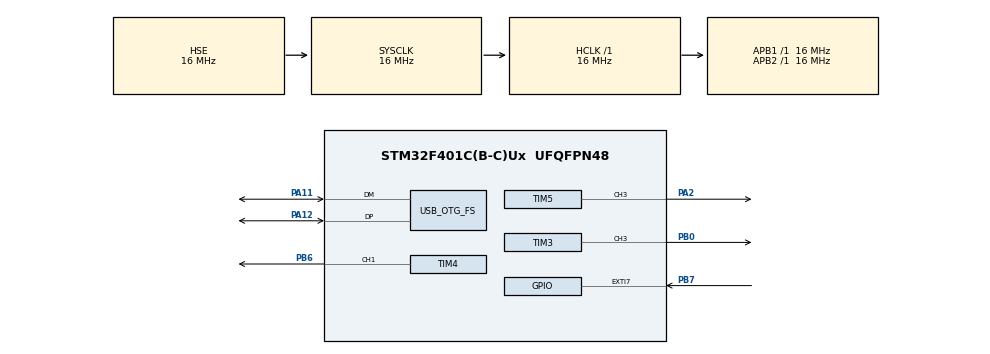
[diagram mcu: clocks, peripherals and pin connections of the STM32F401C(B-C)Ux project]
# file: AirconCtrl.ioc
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IWDG.Reload=4095
Mcu.Family=STM32F4
Mcu.Name=STM32F401C(B-C)Ux
Mcu.Package=UFQFPN48
NVIC.EXTI9_5_IRQn=true\:0\:0\:false\:false\:true\:true\:true\:true
NVIC.OTG_FS_IRQn=true\:0\:0\:false\:false\:true\:false\:true\:true
NVIC.PriorityGroup=NVIC_PRIORITYGROUP_4
NVIC.TIM2_IRQn=true\:0\:0\:false\:false\:true\:true\:true\:true
NVIC.TIM5_IRQn=true\:0\:0\:false\:false\:true\:true\:true\:true
PA11.Mode=Device_Only
PA11.Signal=USB_OTG_FS_DM
PA12.Mode=Device_Only
PA12.Signal=USB_OTG_FS_DP
PA13.Mode=Serial_Wire
PA13.Signal=SYS_JTMS-SWDIO
PA14.Mode=Serial_Wire
PA14.Signal=SYS_JTCK-SWCLK
PA2.Signal=S_TIM5_CH3
PB0.Signal=S_TIM3_CH3
PB6.Signal=S_TIM4_CH1
PB7.GPIO_ModeDefaultEXTI=GPIO_MODE_IT_FALLING
PB7.Signal=GPXTI7
PH0\ -\ OSC_IN.Mode=HSE-External-Oscillator
PH0\ -\ OSC_IN.Signal=RCC_OSC_IN
PH1\ -\ OSC_OUT.Mode=HSE-External-Oscillator
PH1\ -\ OSC_OUT.Signal=RCC_OSC_OUT
ProjectManager.HeapSize=0x200
ProjectManager.StackSize=0x400
ProjectManager.TargetToolchain=Makefile
RCC.48MHZClocksFreq_Value=48000000
RCC.AHBFreq_Value=16000000
RCC.APB1Freq_Value=16000000
RCC.APB2Freq_Value=16000000
RCC.CortexFreq_Value=16000000
RCC.HSE_VALUE=16000000
RCC.HSI_VALUE=16000000
RCC.LSE_VALUE=32768
RCC.PLLM=8
RCC.PLLN=72
RCC.PLLQ=3
RCC.SYSCLKFreq_VALUE=16000000
RCC.SYSCLKSource=RCC_SYSCLKSOURCE_HSE
RCC.VCOOutputFreq_Value=144000000
SH.S_TIM3_CH3.0=TIM3_CH3,PWM Generation3 CH3
SH.S_TIM4_CH1.0=TIM4_CH1,PWM Generation1 CH1
SH.S_TIM5_CH3.0=TIM5_CH3,PWM Generation3 CH3
TIM1.Prescaler=159
TIM2.AutoReloadPreload=TIM_AUTORELOAD_PRELOAD_ENABLE
TIM2.Period=99
TIM2.Prescaler=15999
TIM2.TIM_MasterOutputTrigger=TIM_TRGO_UPDATE
TIM2.TIM_MasterSlaveMode=TIM_MASTERSLAVEMODE_ENABLE
TIM3.AutoReloadPreload=TIM_AUTORELOAD_PRELOAD_ENABLE
TIM3.Channel-PWM\ Generation3\ CH3=TIM_CHANNEL_3
TIM3.OCMode_PWM-PWM\ Generation3\ CH3=TIM_OCMODE_PWM1
TIM3.OCPolarity_3=TIM_OCPOLARITY_LOW
TIM3.Period=420
TIM3.Pulse-PWM\ Generation3\ CH3=150
TIM3.TIM_MasterOutputTrigger=TIM_TRGO_UPDATE
TIM3.TIM_MasterSlaveMode=TIM_MASTERSLAVEMODE_ENABLE
TIM4.AutoReloadPreload=TIM_AUTORELOAD_PRELOAD_ENABLE
TIM4.Channel-PWM\ Generation1\ CH1=TIM_CHANNEL_1
TIM4.OCFastMode_PWM-PWM\ Generation1\ CH1=TIM_OCFAST_DISABLE
TIM4.Period=420
TIM4.Pulse-PWM\ Generation1\ CH1=150
TIM4.TIM_MasterOutputTrigger=TIM_TRGO_UPDATE
TIM4.TIM_MasterSlaveMode=TIM_MASTERSLAVEMODE_ENABLE
TIM5.AutoReloadPreload=TIM_AUTORELOAD_PRELOAD_ENABLE
TIM5.Channel-PWM\ Generation3\ CH3=TIM_CHANNEL_3
TIM5.Period=27839
TIM5.Prescaler=1
TIM5.TIM_MasterOutputTrigger=TIM_TRGO_UPDATE
TIM5.TIM_MasterSlaveMode=TIM_MASTERSLAVEMODE_ENABLE
USB_DEVICE.CLASS_NAME_FS=CDC
USB_DEVICE.VirtualMode=Cdc
USB_DEVICE.VirtualModeFS=Cdc_FS
USB_OTG_FS.VirtualMode=Device_Only
VP_IWDG_VS_IWDG.Mode=IWDG_Activate
VP_TIM1_VS_ClockSourceINT.Mode=Internal
VP_TIM2_VS_ClockSourceINT.Mode=Internal
VP_TIM5_VS_ClockSourceINT.Mode=Internal
VP_USB_DEVICE_VS_USB_DEVICE_CDC_FS.Mode=CDC_FS
VP_WWDG_VS_WWDG.Mode=WWDG_Activate
WWDG.Counter=118
WWDG.Prescaler=WWDG_PRESCALER_8
WWDG.Window=74
board=custom

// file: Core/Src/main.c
/* USER CODE BEGIN Header */
/**
  ******************************************************************************
  * @file           : main.c
  * @brief          : Main program body
  ******************************************************************************
  * @attention
  *
  * Copyright (c) 2022 STMicroelectronics.
  * All rights reserved.
  *
  * This software is licensed under terms that can be found in the LICENSE file
  * in the root directory of this software component.
  * If no LICENSE file comes with this software, it is provided AS-IS.
  *
  ******************************************************************************
  */
/* USER CODE END Header */
#include "main.h"
#include "usb_device.h"

/* USER CODE BEGIN Includes */
#include "airconCtrl.h"
#include "transmitterIR.h"
#include "CAProtocolStm.h"
/* USER CODE END Includes */

IWDG_HandleTypeDef hiwdg;

TIM_HandleTypeDef htim1;
TIM_HandleTypeDef htim2;
TIM_HandleTypeDef htim3;
TIM_HandleTypeDef htim4;
TIM_HandleTypeDef htim5;

WWDG_HandleTypeDef hwwdg;

void SystemClock_Config(void);
static void MX_GPIO_Init(void);
static void MX_TIM1_Init(void);
static void MX_TIM4_Init(void);
static void MX_WWDG_Init(void);
static void MX_TIM2_Init(void);
static void MX_IWDG_Init(void);
static void MX_TIM5_Init(void);
static void MX_TIM3_Init(void);

int main(void)
{

  /* MCU Configuration--------------------------------------------------------*/

  /* Reset of all peripherals, Initializes the Flash interface and the Systick. */
  HAL_Init();

  /* USER CODE BEGIN Init */
  const char *bootMsg = CAonBoot();
  /* USER CODE END Init */

  /* Configure the system clock */
  SystemClock_Config();

  /* Initialize all configured peripherals */
  MX_GPIO_Init();
  MX_USB_DEVICE_Init();
  MX_TIM1_Init();
  MX_TIM4_Init();
  MX_WWDG_Init();
  MX_TIM2_Init();
  MX_IWDG_Init();
  MX_TIM5_Init();
  MX_TIM3_Init();
  /* USER CODE BEGIN 2 */
  // Timer needs to be started outside init function
  // otherwise wwdg will timeout upon startup
  HAL_TIM_Base_Start_IT(&htim2);

  airconCtrlInit(&htim1, &htim2, &hwwdg);
  initTransmitterIR(&htim4, &htim3, &htim5);
  /* USER CODE END 2 */

  /* Infinite loop */
  /* USER CODE BEGIN WHILE */
  while (1)
  {
	HAL_IWDG_Refresh(&hiwdg);
	airconCtrlLoop(bootMsg);
    /* USER CODE END WHILE */

  }
}

void SystemClock_Config(void)
{
  RCC_OscInitTypeDef RCC_OscInitStruct = {0};
  RCC_ClkInitTypeDef RCC_ClkInitStruct = {0};

  /** Configure the main internal regulator output voltage
  */
  __HAL_RCC_PWR_CLK_ENABLE();
  __HAL_PWR_VOLTAGESCALING_CONFIG(PWR_REGULATOR_VOLTAGE_SCALE2);

  /** Initializes the RCC Oscillators according to the specified parameters
  * in the RCC_OscInitTypeDef structure.
  */
  RCC_OscInitStruct.OscillatorType = RCC_OSCILLATORTYPE_LSI|RCC_OSCILLATORTYPE_HSE;
  RCC_OscInitStruct.HSEState = RCC_HSE_ON;
  RCC_OscInitStruct.LSIState = RCC_LSI_ON;
  RCC_OscInitStruct.PLL.PLLState = RCC_PLL_ON;
  RCC_OscInitStruct.PLL.PLLSource = RCC_PLLSOURCE_HSE;
  RCC_OscInitStruct.PLL.PLLM = 8;
  RCC_OscInitStruct.PLL.PLLN = 72;
  RCC_OscInitStruct.PLL.PLLP = RCC_PLLP_DIV2;
  RCC_OscInitStruct.PLL.PLLQ = 3;
  if (HAL_RCC_OscConfig(&RCC_OscInitStruct) != HAL_OK)
  {
    Error_Handler();
  }

  /** Initializes the CPU, AHB and APB buses clocks
  */
  RCC_ClkInitStruct.ClockType = RCC_CLOCKTYPE_HCLK|RCC_CLOCKTYPE_SYSCLK
                              |RCC_CLOCKTYPE_PCLK1|RCC_CLOCKTYPE_PCLK2;
  RCC_ClkInitStruct.SYSCLKSource = RCC_SYSCLKSOURCE_HSE;
  RCC_ClkInitStruct.AHBCLKDivider = RCC_SYSCLK_DIV1;
  RCC_ClkInitStruct.APB1CLKDivider = RCC_HCLK_DIV1;
  RCC_ClkInitStruct.APB2CLKDivider = RCC_HCLK_DIV1;

  if (HAL_RCC_ClockConfig(&RCC_ClkInitStruct, FLASH_LATENCY_0) != HAL_OK)
  {
    Error_Handler();
  }
}

static void MX_IWDG_Init(void)
{

  hiwdg.Instance = IWDG;
  hiwdg.Init.Prescaler = IWDG_PRESCALER_4;
  hiwdg.Init.Reload = 4095;
  if (HAL_IWDG_Init(&hiwdg) != HAL_OK)
  {
    Error_Handler();
  }

}

static void MX_TIM1_Init(void)
{

  TIM_ClockConfigTypeDef sClockSourceConfig = {0};
  TIM_MasterConfigTypeDef sMasterConfig = {0};

  htim1.Instance = TIM1;
  htim1.Init.Prescaler = 159;
  htim1.Init.CounterMode = TIM_COUNTERMODE_UP;
  htim1.Init.Period = 65535;
  htim1.Init.ClockDivision = TIM_CLOCKDIVISION_DIV1;
  htim1.Init.RepetitionCounter = 0;
  htim1.Init.AutoReloadPreload = TIM_AUTORELOAD_PRELOAD_DISABLE;
  if (HAL_TIM_Base_Init(&htim1) != HAL_OK)
  {
    Error_Handler();
  }
  sClockSourceConfig.ClockSource = TIM_CLOCKSOURCE_INTERNAL;
  if (HAL_TIM_ConfigClockSource(&htim1, &sClockSourceConfig) != HAL_OK)
  {
    Error_Handler();
  }
  sMasterConfig.MasterOutputTrigger = TIM_TRGO_RESET;
  sMasterConfig.MasterSlaveMode = TIM_MASTERSLAVEMODE_DISABLE;
  if (HAL_TIMEx_MasterConfigSynchronization(&htim1, &sMasterConfig) != HAL_OK)
  {
    Error_Handler();
  }

}

static void MX_TIM2_Init(void)
{

  TIM_ClockConfigTypeDef sClockSourceConfig = {0};
  TIM_MasterConfigTypeDef sMasterConfig = {0};

  htim2.Instance = TIM2;
  htim2.Init.Prescaler = 15999;
  htim2.Init.CounterMode = TIM_COUNTERMODE_UP;
  htim2.Init.Period = 99;
  htim2.Init.ClockDivision = TIM_CLOCKDIVISION_DIV1;
  htim2.Init.AutoReloadPreload = TIM_AUTORELOAD_PRELOAD_ENABLE;
  if (HAL_TIM_Base_Init(&htim2) != HAL_OK)
  {
    Error_Handler();
  }
  sClockSourceConfig.ClockSource = TIM_CLOCKSOURCE_INTERNAL;
  if (HAL_TIM_ConfigClockSource(&htim2, &sClockSourceConfig) != HAL_OK)
  {
    Error_Handler();
  }
  sMasterConfig.MasterOutputTrigger = TIM_TRGO_UPDATE;
  sMasterConfig.MasterSlaveMode = TIM_MASTERSLAVEMODE_ENABLE;
  if (HAL_TIMEx_MasterConfigSynchronization(&htim2, &sMasterConfig) != HAL_OK)
  {
    Error_Handler();
  }

}

static void MX_TIM3_Init(void)
{

  TIM_MasterConfigTypeDef sMasterConfig = {0};
  TIM_OC_InitTypeDef sConfigOC = {0};

  htim3.Instance = TIM3;
  htim3.Init.Prescaler = 0;
  htim3.Init.CounterMode = TIM_COUNTERMODE_UP;
  htim3.Init.Period = 420;
  htim3.Init.ClockDivision = TIM_CLOCKDIVISION_DIV1;
  htim3.Init.AutoReloadPreload = TIM_AUTORELOAD_PRELOAD_ENABLE;
  if (HAL_TIM_PWM_Init(&htim3) != HAL_OK)
  {
    Error_Handler();
  }
  sMasterConfig.MasterOutputTrigger = TIM_TRGO_UPDATE;
  sMasterConfig.MasterSlaveMode = TIM_MASTERSLAVEMODE_ENABLE;
  if (HAL_TIMEx_MasterConfigSynchronization(&htim3, &sMasterConfig) != HAL_OK)
  {
    Error_Handler();
  }
  sConfigOC.OCMode = TIM_OCMODE_PWM1;
  sConfigOC.Pulse = 150;
  sConfigOC.OCPolarity = TIM_OCPOLARITY_LOW;
  sConfigOC.OCFastMode = TIM_OCFAST_DISABLE;
  if (HAL_TIM_PWM_ConfigChannel(&htim3, &sConfigOC, TIM_CHANNEL_3) != HAL_OK)
  {
    Error_Handler();
  }
  HAL_TIM_MspPostInit(&htim3);

}

static void MX_TIM4_Init(void)
{

  TIM_MasterConfigTypeDef sMasterConfig = {0};
  TIM_OC_InitTypeDef sConfigOC = {0};

  htim4.Instance = TIM4;
  htim4.Init.Prescaler = 0;
  htim4.Init.CounterMode = TIM_COUNTERMODE_UP;
  htim4.Init.Period = 420;
  htim4.Init.ClockDivision = TIM_CLOCKDIVISION_DIV1;
  htim4.Init.AutoReloadPreload = TIM_AUTORELOAD_PRELOAD_ENABLE;
  if (HAL_TIM_PWM_Init(&htim4) != HAL_OK)
  {
    Error_Handler();
  }
  sMasterConfig.MasterOutputTrigger = TIM_TRGO_UPDATE;
  sMasterConfig.MasterSlaveMode = TIM_MASTERSLAVEMODE_ENABLE;
  if (HAL_TIMEx_MasterConfigSynchronization(&htim4, &sMasterConfig) != HAL_OK)
  {
    Error_Handler();
  }
  sConfigOC.OCMode = TIM_OCMODE_PWM1;
  sConfigOC.Pulse = 150;
  sConfigOC.OCPolarity = TIM_OCPOLARITY_HIGH;
  sConfigOC.OCFastMode = TIM_OCFAST_DISABLE;
  if (HAL_TIM_PWM_ConfigChannel(&htim4, &sConfigOC, TIM_CHANNEL_1) != HAL_OK)
  {
    Error_Handler();
  }
  HAL_TIM_MspPostInit(&htim4);

}

static void MX_TIM5_Init(void)
{

  TIM_ClockConfigTypeDef sClockSourceConfig = {0};
  TIM_MasterConfigTypeDef sMasterConfig = {0};
  TIM_OC_InitTypeDef sConfigOC = {0};

  htim5.Instance = TIM5;
  htim5.Init.Prescaler = 1;
  htim5.Init.CounterMode = TIM_COUNTERMODE_UP;
  htim5.Init.Period = 27839;
  htim5.Init.ClockDivision = TIM_CLOCKDIVISION_DIV1;
  htim5.Init.AutoReloadPreload = TIM_AUTORELOAD_PRELOAD_ENABLE;
  if (HAL_TIM_Base_Init(&htim5) != HAL_OK)
  {
    Error_Handler();
  }
  sClockSourceConfig.ClockSource = TIM_CLOCKSOURCE_INTERNAL;
  if (HAL_TIM_ConfigClockSource(&htim5, &sClockSourceConfig) != HAL_OK)
  {
    Error_Handler();
  }
  if (HAL_TIM_PWM_Init(&htim5) != HAL_OK)
  {
    Error_Handler();
  }
  sMasterConfig.MasterOutputTrigger = TIM_TRGO_UPDATE;
  sMasterConfig.MasterSlaveMode = TIM_MASTERSLAVEMODE_ENABLE;
  if (HAL_TIMEx_MasterConfigSynchronization(&htim5, &sMasterConfig) != HAL_OK)
  {
    Error_Handler();
  }
  sConfigOC.OCMode = TIM_OCMODE_PWM1;
  sConfigOC.Pulse = 0;
  sConfigOC.OCPolarity = TIM_OCPOLARITY_HIGH;
  sConfigOC.OCFastMode = TIM_OCFAST_DISABLE;
  if (HAL_TIM_PWM_ConfigChannel(&htim5, &sConfigOC, TIM_CHANNEL_3) != HAL_OK)
  {
    Error_Handler();
  }
  HAL_TIM_MspPostInit(&htim5);

}

static void MX_WWDG_Init(void)
{

  hwwdg.Instance = WWDG;
  hwwdg.Init.Prescaler = WWDG_PRESCALER_8;
  hwwdg.Init.Window = 74;
  hwwdg.Init.Counter = 118;
  hwwdg.Init.EWIMode = WWDG_EWI_DISABLE;
  if (HAL_WWDG_Init(&hwwdg) != HAL_OK)
  {
    Error_Handler();
  }

}

static void MX_GPIO_Init(void)
{
  GPIO_InitTypeDef GPIO_InitStruct = {0};

  /* GPIO Ports Clock Enable */
  __HAL_RCC_GPIOH_CLK_ENABLE();
  __HAL_RCC_GPIOA_CLK_ENABLE();
  __HAL_RCC_GPIOB_CLK_ENABLE();

  /*Configure GPIO pin : PB7 */
  GPIO_InitStruct.Pin = GPIO_PIN_7;
  GPIO_InitStruct.Mode = GPIO_MODE_IT_FALLING;
  GPIO_InitStruct.Pull = GPIO_NOPULL;
  HAL_GPIO_Init(GPIOB, &GPIO_InitStruct);

  /* EXTI interrupt init*/
  HAL_NVIC_SetPriority(EXTI9_5_IRQn, 0, 0);
  HAL_NVIC_EnableIRQ(EXTI9_5_IRQn);

}

void Error_Handler(void)
{
  __disable_irq();
  while (1)
  {
  }
}
